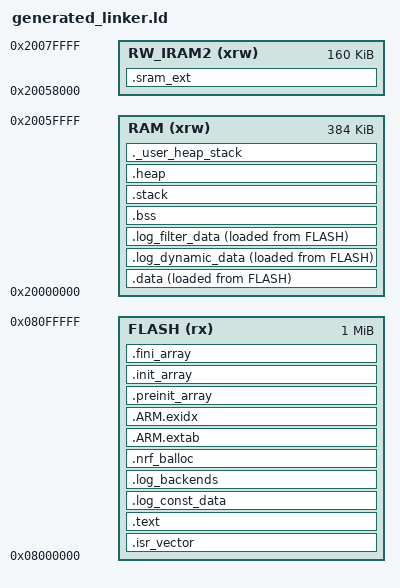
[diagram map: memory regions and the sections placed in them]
/* Auto-generated fallback linker script from uvprojx memory info */
ENTRY(Reset_Handler)

_estack = ORIGIN(RAM) + LENGTH(RAM);
_sstack = ORIGIN(RAM);
_Min_Heap_Size = 0x400;
_Min_Stack_Size = 0x400;

MEMORY
{
  FLASH (rx)  : ORIGIN = 0x08000000, LENGTH = 0x100000
  RAM   (xrw) : ORIGIN = 0x20000000, LENGTH = 0x60000
  RW_IRAM2 (xrw) : ORIGIN = 0x20058000, LENGTH = 0x28000
}

SECTIONS
{
  .isr_vector :
  {
    . = ALIGN(4);
    KEEP(*(.isr_vector))
    . = ALIGN(4);
  } > FLASH

  .text :
  {
    . = ALIGN(4);
    *(.text*)
    *(.rodata*)
    *(.glue_7)
    *(.glue_7t)
    *(.eh_frame)
    KEEP (*(.init))
    KEEP (*(.fini))
    . = ALIGN(4);
    _etext = .;
    _stext = ADDR(.text);
  } > FLASH

  .log_const_data :
  {
    PROVIDE(__start_log_const_data = .);
    KEEP(*(SORT(.log_const_data*)))
    PROVIDE(__stop_log_const_data = .);
  } > FLASH

  .log_backends :
  {
    PROVIDE(__start_log_backends = .);
    KEEP(*(SORT(.log_backends*)))
    PROVIDE(__stop_log_backends = .);
  } > FLASH

  .nrf_balloc :
  {
    PROVIDE(__start_nrf_balloc = .);
    KEEP(*(.nrf_balloc))
    PROVIDE(__stop_nrf_balloc = .);
  } > FLASH

  .ARM.extab : { *(.ARM.extab* .gnu.linkonce.armextab.*) } > FLASH
  .ARM.exidx :
  {
    __exidx_start = .;
    *(.ARM.exidx*)
    __exidx_end = .;
  } > FLASH

  .preinit_array :
  {
    PROVIDE_HIDDEN (__preinit_array_start = .);
    KEEP (*(.preinit_array*))
    PROVIDE_HIDDEN (__preinit_array_end = .);
  } > FLASH

  .init_array :
  {
    PROVIDE_HIDDEN (__init_array_start = .);
    KEEP (*(SORT(.init_array.*)))
    KEEP (*(.init_array*))
    PROVIDE_HIDDEN (__init_array_end = .);
  } > FLASH

  .fini_array :
  {
    PROVIDE_HIDDEN (__fini_array_start = .);
    KEEP (*(SORT(.fini_array.*)))
    KEEP (*(.fini_array*))
    PROVIDE_HIDDEN (__fini_array_end = .);
  } > FLASH

  _sidata = LOADADDR(.data);
  .data :
  {
    . = ALIGN(4);
    _sdata = .;
    *(.data*)
    . = ALIGN(4);
    _edata = .;
  } > RAM AT > FLASH

  .log_dynamic_data :
  {
    PROVIDE(__start_log_dynamic_data = .);
    KEEP(*(SORT(.log_dynamic_data*)))
    PROVIDE(__stop_log_dynamic_data = .);
  } > RAM AT > FLASH

  .log_filter_data :
  {
    PROVIDE(__start_log_filter_data = .);
    KEEP(*(SORT(.log_filter_data*)))
    PROVIDE(__stop_log_filter_data = .);
  } > RAM AT > FLASH

  .bss :
  {
    . = ALIGN(4);
    _sbss = .;
    *(.bss*)
    *(COMMON)
    . = ALIGN(4);
    _ebss = .;
  } > RAM

  .stack (NOLOAD) :
  {
    . = ALIGN(8);
    KEEP(*(.stack))
    . = ALIGN(8);
  } > RAM

  .heap (NOLOAD) :
  {
    . = ALIGN(8);
    KEEP(*(.heap))
    . = ALIGN(8);
  } > RAM

  .sram_ext (NOLOAD) :
  {
    . = ALIGN(4);
    *(.sram_ext)
    *(.sram_ext.*)
    . = ALIGN(4);
  } > RW_IRAM2


  ._user_heap_stack :
  {
    . = ALIGN(8);
    PROVIDE(end = .);
    . = . + _Min_Heap_Size;
    . = . + _Min_Stack_Size;
    . = ALIGN(8);
  } > RAM

  /DISCARD/ : { *(.note.GNU-stack) }
}
